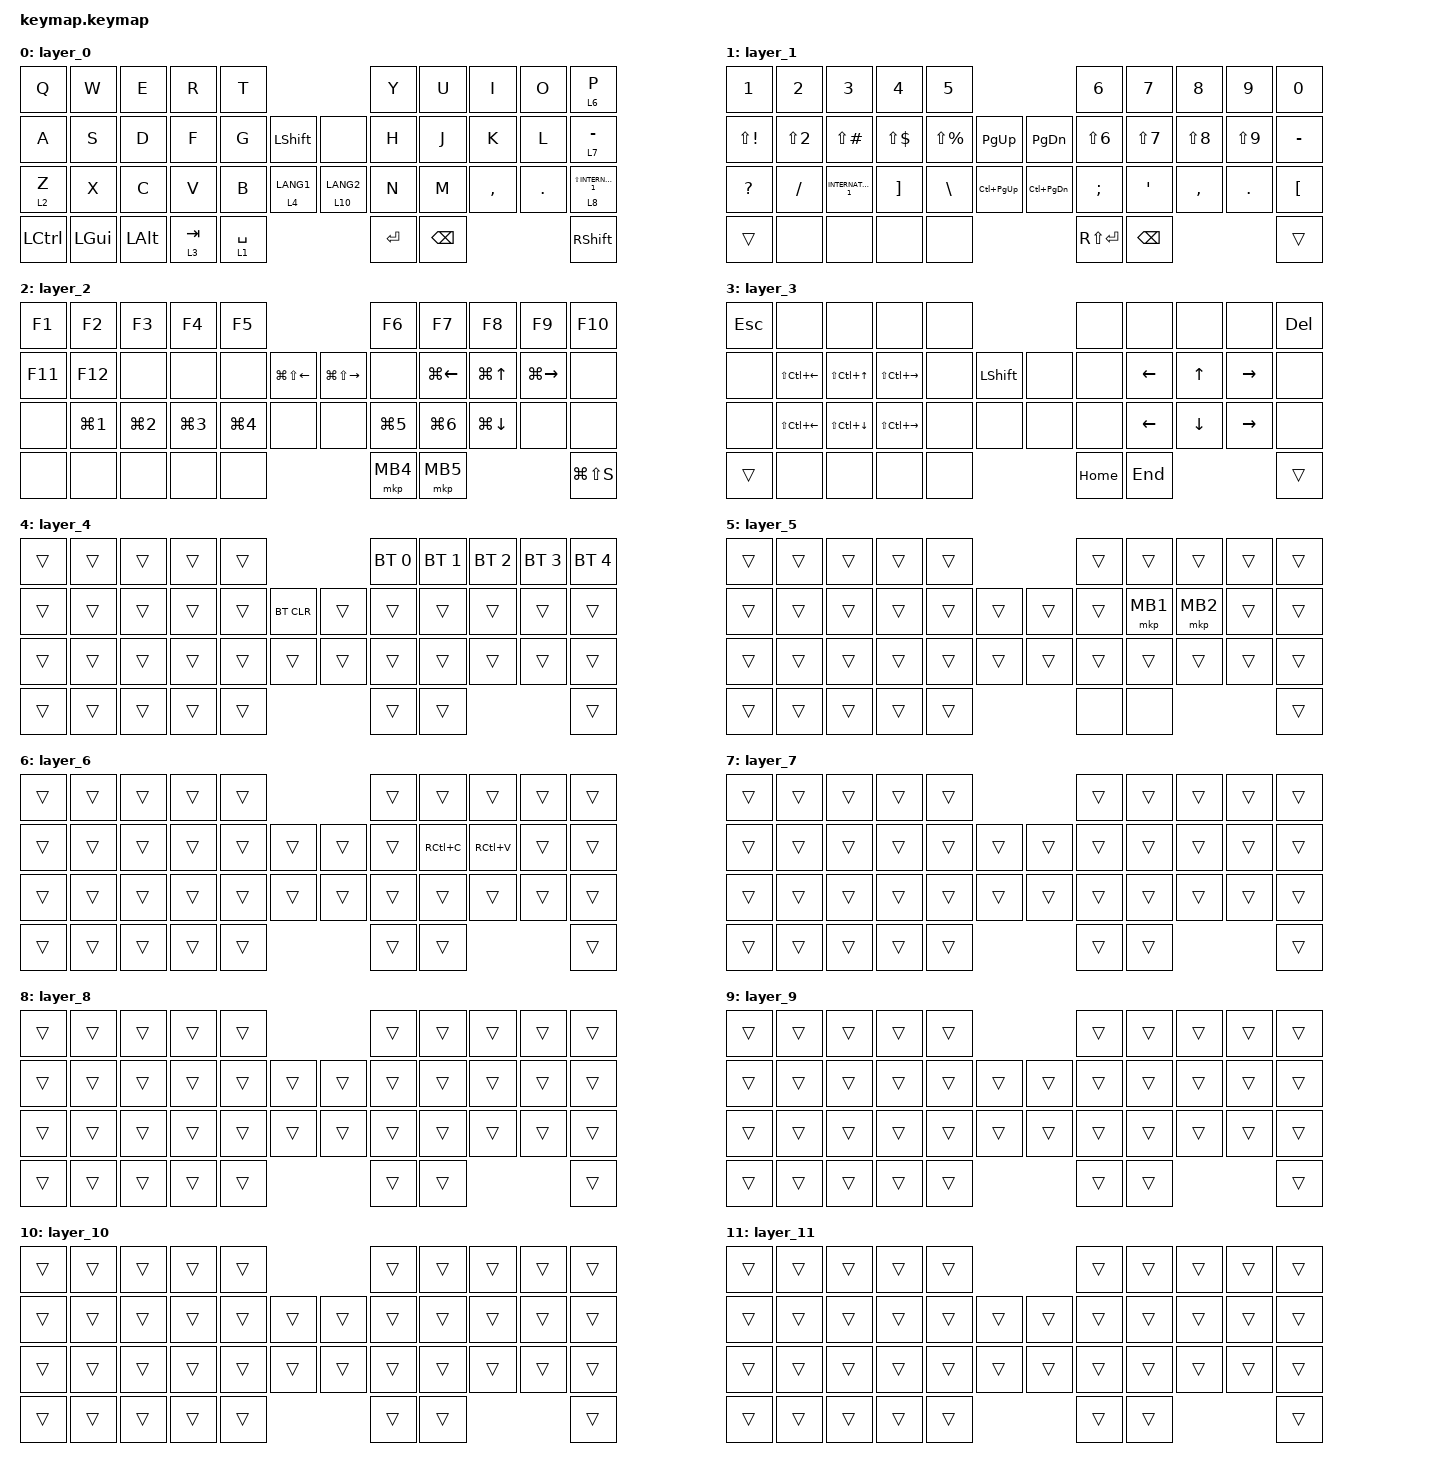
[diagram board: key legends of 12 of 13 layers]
#include <mouse-gesture.dtsi>
#include <behaviors.dtsi>
#include <dt-bindings/zmk/bt.h>
#include <dt-bindings/zmk/keys.h>
#include <dt-bindings/zmk/pointing.h>

/ {
    combos { compatible = "zmk,combos"; };

    behaviors {
        // 標準のHold-Tap全般の長押し判定時間を変更（例: 100msに設定）

        hold_tap: hold_tap { tapping-term-ms = <100>; };
    };

    keymap {
        compatible = "zmk,keymap";

        layer_0 {
            bindings = <
&kp Q             &kp W     &kp E     &kp R      &kp T                                      &kp Y      &kp U          &kp I      &kp O       &lt 6 P
&kp A             &kp S     &kp D     &kp F      &kp G        &kp LEFT_SHIFT  &none         &kp H      &kp J          &kp K      &kp L       &lt 7 MINUS
&lt 2 Z           &kp X     &kp C     &kp V      &kp B        &lt 4 LANG1     &lt 10 LANG2  &kp N      &kp M          &kp COMMA  &kp PERIOD  &lt 8 LS(INTERNATIONAL_1)
&kp LEFT_CONTROL  &kp LGUI  &kp LALT  &lt 3 TAB  &lt 1 SPACE                                &kp ENTER  &kp BACKSPACE                         &kp RSHFT
            >;
        };

        layer_1 {
            bindings = <
&kp N1        &kp N2            &kp N3               &kp N4             &kp N5                                             &kp N6            &kp N7         &kp N8      &kp N9      &kp N0
&kp LS(EXCL)  &kp LS(NUMBER_2)  &kp LS(POUND)        &kp LS(DLLR)       &kp LS(PRCNT)  &kp PAGE_UP      &kp PAGE_DOWN      &kp LS(NUMBER_6)  &kp LS(N7)     &kp LS(N8)  &kp LS(N9)  &kp MINUS
&kp QUESTION  &kp SLASH         &kp INTERNATIONAL_1  &kp RIGHT_BRACKET  &kp BSLH       &kp LC(PAGE_UP)  &kp LC(PAGE_DOWN)  &kp SEMICOLON     &kp SQT        &kp COMMA   &kp PERIOD  &kp LEFT_BRACKET
&trans        &none             &none                &none              &none                                              &kp RS(ENTER)     &kp BACKSPACE                          &trans
            >;
        };

        layer_2 {
            bindings = <
&kp F1   &kp F2      &kp F3      &kp F4      &kp F5                                           &kp F6      &kp F7            &kp F8            &kp F9         &kp F10
&kp F11  &kp F12     &none       &none       &none       &kp LG(LS(LEFT))  &kp LG(LS(RIGHT))  &none       &kp LG(LEFT)      &kp LG(UP_ARROW)  &kp LG(RIGHT)  &none
&none    &kp LG(N1)  &kp LG(N2)  &kp LG(N3)  &kp LG(N4)  &none             &none              &kp LG(N5)  &kp LG(NUMBER_6)  &kp LG(DOWN)      &none          &none
&none    &none       &none       &none       &none                                            &mkp MB4    &mkp MB5                                           &kp LG(LS(S))
            >;
        };

        layer_3 {
            bindings = <
&kp ESCAPE  &none                   &none                 &none                    &none                         &none     &none     &none     &none      &kp DELETE
&none       &kp LS(LC(LEFT_ARROW))  &kp LS(LC(UP_ARROW))  &kp LS(LC(RIGHT))        &none  &kp LEFT_SHIFT  &none  &none     &kp LEFT  &kp UP    &kp RIGHT  &none
&none       &kp LS(LC(LEFT_ARROW))  &kp LS(LC(DOWN))      &kp LS(LC(RIGHT_ARROW))  &none  &none           &none  &none     &kp LEFT  &kp DOWN  &kp RIGHT  &none
&trans      &none                   &none                 &none                    &none                         &kp HOME  &kp END                        &trans
            >;
        };

        layer_4 {
            bindings = <
&trans  &trans  &trans  &trans  &trans                      &bt BT_SEL 0  &bt BT_SEL 1  &bt BT_SEL 2  &bt BT_SEL 3  &bt BT_SEL 4
&trans  &trans  &trans  &trans  &trans  &bt BT_CLR  &trans  &trans        &trans        &trans        &trans        &trans
&trans  &trans  &trans  &trans  &trans  &trans      &trans  &trans        &trans        &trans        &trans        &trans
&trans  &trans  &trans  &trans  &trans                      &trans        &trans                                    &trans
            >;
        };

        layer_5 {
            bindings = <
&trans  &trans  &trans  &trans  &trans                  &trans  &trans    &trans    &trans  &trans
&trans  &trans  &trans  &trans  &trans  &trans  &trans  &trans  &mkp MB1  &mkp MB2  &trans  &trans
&trans  &trans  &trans  &trans  &trans  &trans  &trans  &trans  &trans    &trans    &trans  &trans
&trans  &trans  &trans  &trans  &trans                  &none   &none                       &trans
            >;
        };

        layer_6 {
            bindings = <
&trans  &trans  &trans  &trans  &trans                  &trans  &trans     &trans     &trans  &trans
&trans  &trans  &trans  &trans  &trans  &trans  &trans  &trans  &kp RC(C)  &kp RC(V)  &trans  &trans
&trans  &trans  &trans  &trans  &trans  &trans  &trans  &trans  &trans     &trans     &trans  &trans
&trans  &trans  &trans  &trans  &trans                  &trans  &trans                        &trans
            >;
        };

        layer_7 {
            bindings = <
&trans  &trans  &trans  &trans  &trans                  &trans  &trans  &trans  &trans  &trans
&trans  &trans  &trans  &trans  &trans  &trans  &trans  &trans  &trans  &trans  &trans  &trans
&trans  &trans  &trans  &trans  &trans  &trans  &trans  &trans  &trans  &trans  &trans  &trans
&trans  &trans  &trans  &trans  &trans                  &trans  &trans                  &trans
            >;
        };

        layer_8 {
            bindings = <
&trans  &trans  &trans  &trans  &trans                  &trans  &trans  &trans  &trans  &trans
&trans  &trans  &trans  &trans  &trans  &trans  &trans  &trans  &trans  &trans  &trans  &trans
&trans  &trans  &trans  &trans  &trans  &trans  &trans  &trans  &trans  &trans  &trans  &trans
&trans  &trans  &trans  &trans  &trans                  &trans  &trans                  &trans
            >;
        };

        layer_9 {
            bindings = <
&trans  &trans  &trans  &trans  &trans                  &trans  &trans  &trans  &trans  &trans
&trans  &trans  &trans  &trans  &trans  &trans  &trans  &trans  &trans  &trans  &trans  &trans
&trans  &trans  &trans  &trans  &trans  &trans  &trans  &trans  &trans  &trans  &trans  &trans
&trans  &trans  &trans  &trans  &trans                  &trans  &trans                  &trans
            >;
        };

        layer_10 {
            bindings = <
&trans  &trans  &trans  &trans  &trans                  &trans  &trans  &trans  &trans  &trans
&trans  &trans  &trans  &trans  &trans  &trans  &trans  &trans  &trans  &trans  &trans  &trans
&trans  &trans  &trans  &trans  &trans  &trans  &trans  &trans  &trans  &trans  &trans  &trans
&trans  &trans  &trans  &trans  &trans                  &trans  &trans                  &trans
            >;
        };

        layer_11 {
            bindings = <
&trans  &trans  &trans  &trans  &trans                  &trans  &trans  &trans  &trans  &trans
&trans  &trans  &trans  &trans  &trans  &trans  &trans  &trans  &trans  &trans  &trans  &trans
&trans  &trans  &trans  &trans  &trans  &trans  &trans  &trans  &trans  &trans  &trans  &trans
&trans  &trans  &trans  &trans  &trans                  &trans  &trans                  &trans
            >;
        };

        layer_12 {
            bindings = <
&trans  &trans  &trans  &trans  &trans                  &trans  &trans  &trans  &trans  &trans
&trans  &trans  &trans  &trans  &trans  &trans  &trans  &trans  &trans  &trans  &trans  &trans
&trans  &trans  &trans  &trans  &trans  &trans  &trans  &trans  &trans  &trans  &trans  &trans
&trans  &trans  &trans  &trans  &trans                  &trans  &trans                  &trans
            >;
        };
    };
};

&zip_mouse_gesture {
    stroke-size = <5>;
    idle-timeout-ms = <3>;
    always-active;

    /* 右ジェスチャー：Ctrl + Page Down */

    gesture_right {
        pattern = <GESTURE_RIGHT>;
        bindings = <&kp LC(PAGE_DOWN)>;
    };

    /* 左ジェスチャー：Ctrl + Page Up */

    gesture_left {
        pattern = <GESTURE_LEFT>;
        bindings = <&kp LC(PAGE_UP)>;
    };

    /* 下: タブを閉じる */

    gesture_down {
        pattern = <GESTURE_DOWN>;
        bindings = <&kp LC(W)>;
    };

    /* 上: 新規タブを開く */

    gesture_up {
        pattern = <GESTURE_UP>;
        bindings = <&kp LC(T)>;
    };
};
